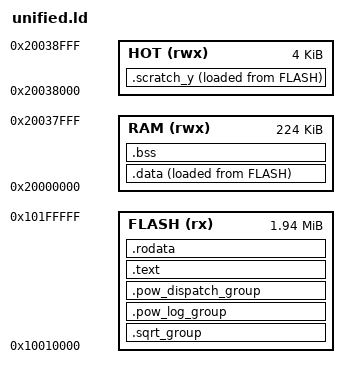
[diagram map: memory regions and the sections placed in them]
EXTERN(_ZN12compact_math2lnEd _ZN12compact_math3cosEd _ZN12compact_math3expEd _ZN12compact_math3powEdd _ZN12compact_math3sinEd _ZN12compact_math3tanEd _ZN12compact_math4acosEd _ZN12compact_math4asinEd _ZN12compact_math4atanEd _ZN12compact_math4sqrtEd _ZN12compact_math5log10Ed __aeabi_d2f __aeabi_d2iz __aeabi_d2lz __aeabi_d2uiz __aeabi_d2ulz __aeabi_dadd __aeabi_dcmpeq __aeabi_dcmpge __aeabi_dcmpgt __aeabi_dcmple __aeabi_dcmplt __aeabi_dcmpun __aeabi_ddiv __aeabi_dmul __aeabi_drsub __aeabi_dsub __aeabi_f2d __aeabi_f2iz __aeabi_f2uiz __aeabi_fadd __aeabi_fcmpeq __aeabi_fcmpge __aeabi_fcmpgt __aeabi_fcmple __aeabi_fcmplt __aeabi_fcmpun __aeabi_fdiv __aeabi_fmul __aeabi_frsub __aeabi_fsub __aeabi_i2d __aeabi_i2f __aeabi_idiv __aeabi_idiv0 __aeabi_idivmod __aeabi_l2d __aeabi_lasr __aeabi_ldiv0 __aeabi_ldivmod __aeabi_llsl __aeabi_llsr __aeabi_lmul __aeabi_mem_init __aeabi_ui2d __aeabi_ui2f __aeabi_uidiv __aeabi_uidivmod __aeabi_ul2d __aeabi_uldivmod mk61_m0_acos mk61_m0_asin mk61_m0_atan mk61_m0_atan_reduced mk61_m0_boundary128 mk61_m0_boundary128_compare mk61_m0_cr_acos mk61_m0_cr_asin mk61_m0_cr_atan mk61_m0_cr_cos mk61_m0_cr_exp mk61_m0_cr_ln mk61_m0_cr_log10 mk61_m0_cr_pow mk61_m0_cr_pow_refined mk61_m0_cr_sin mk61_m0_cr_tan mk61_m0_d2f_slow mk61_m0_d2iz_slow mk61_m0_d2lz_slow mk61_m0_d2ulz_slow mk61_m0_dadd_slow mk61_m0_ddiv_slow mk61_m0_divmod64 mk61_m0_dmul_slow mk61_m0_exp mk61_m0_exp_endpoint mk61_m0_exp_fraction_capture mk61_m0_exp_small_product48 mk61_m0_exp_small_product64 mk61_m0_exp_small_square48 mk61_m0_f2d_slow mk61_m0_fma mk61_m0_inline_seed_begin mk61_m0_inline_seed_done mk61_m0_ln mk61_m0_ln_approx mk61_m0_ln_special mk61_m0_log10 mk61_m0_log10_special mk61_m0_log_cube70 mk61_m0_log_product46 mk61_m0_log_product54 mk61_m0_log_ratio70 mk61_m0_log_ratio70_slow mk61_m0_math_udiv32 mk61_m0_mul_q62 mk61_m0_pow_argument mk61_m0_pow_argument_select mk61_m0_pow_center_quotient_end mk61_m0_pow_dispatch mk61_m0_pow_dispatch_ordinary mk61_m0_pow_exact_small mk61_m0_pow_exp_product mk61_m0_pow_exp_product_flash mk61_m0_pow_exp_table_product mk61_m0_pow_exp_table_product_flash mk61_m0_pow_fast mk61_m0_pow_log_ordinary mk61_m0_pow_log_select mk61_m0_pow_middle_interval mk61_m0_pow_midpoint mk61_m0_pow_near_one_binomial_dispatch mk61_m0_pow_negative_integer_dispatch mk61_m0_pow_positive_checked_dispatch mk61_m0_pow_rescue mk61_m0_pow_rsqrt_boundary mk61_m0_pow_rsqrt_fast mk61_m0_pow_rsqrt_point mk61_m0_pow_small_y mk61_m0_pow_square_exact mk61_m0_pow_tiny_or_cr mk61_m0_product62 mk61_m0_reciprocal1 mk61_m0_reciprocal1_after_second_product mk61_m0_reciprocal1_after_y_residual mk61_m0_reciprocal1_before_second_product mk61_m0_reciprocal1_certificate_begin mk61_m0_reciprocal1_certificate_down mk61_m0_reciprocal1_certificate_full mk61_m0_reciprocal1_certificate_up mk61_m0_reciprocal1_first_product mk61_m0_reciprocal1_half_normalization mk61_m0_reciprocal1_join mk61_m0_reciprocal1_pack_begin mk61_m0_reciprocal1_sw_after_second_product mk61_m0_reciprocal1_sw_after_y_residual mk61_m0_reciprocal1_sw_before_second_product mk61_m0_reciprocal1_sw_certificate_begin mk61_m0_reciprocal1_sw_certificate_down mk61_m0_reciprocal1_sw_certificate_full mk61_m0_reciprocal1_sw_certificate_up mk61_m0_reciprocal1_sw_first_product mk61_m0_reciprocal1_sw_from_guard mk61_m0_reciprocal1_sw_half_normalization mk61_m0_reciprocal1_sw_join mk61_m0_reciprocal1_sw_pack_begin mk61_m0_reciprocal1_sw_y_low_shift mk61_m0_reciprocal1_y_low_shift mk61_m0_reduce_pio2 mk61_m0_sdiv32 mk61_m0_sdivmod64 mk61_m0_sincos_reduced mk61_m0_sincos_small mk61_m0_sqrt mk61_m0_sqrt_slow mk61_m0_sqrt_special mk61_m0_sqrtf mk61_m0_tan_small mk61_m0_trig mk61_m0_trig_inverse_table mk61_m0_trig_large mk61_m0_trig_large_argument mk61_m0_trig_large_refine mk61_m0_trig_medium mk61_m0_trig_pack mk61_m0_trig_pi2_product mk61_m0_trig_product mk61_m0_udiv32 unified_math_init)
MEMORY {
 FLASH(rx) : ORIGIN = 0x10010000, LENGTH = 1984K
 RAM(rwx) : ORIGIN = 0x20000000, LENGTH = 224K
 HOT(rwx) : ORIGIN = 0x20038000, LENGTH = 4K
}
PHDRS { flash PT_LOAD FLAGS(5); hot PT_LOAD FLAGS(5); ram PT_LOAD FLAGS(6); }
SECTIONS {
 .sqrt_group : { *(.m0_sqrt_special) *(.m0_sqrt64_fixed.mk61_m0_sqrt) *(.m0_sqrt64_fixed.*) } > FLASH :flash
 .pow_log_group : { *(.m0_pow_log_selector) *(.m0_pow_extension) } > FLASH :flash
 .pow_dispatch_group : { *(.m0_pow_dispatch_extension) *(.m0_pow_extension_data) *(.m0_pow_argument_extension) } > FLASH :flash
 .text : { *(.text*) *(.m0_*) *(.time_critical*) } > FLASH :flash
 .rodata : { *(.rodata*) *(.data.rel.ro*) } > FLASH :flash
 .scratch_y : ALIGN(4) { __scratch_y_start__ = .; *(.scratch_y*) . = ALIGN(4); __scratch_y_end__ = .; } > HOT AT>FLASH :hot
 __scratch_y_source__ = LOADADDR(.scratch_y);
 .data : ALIGN(4) { __data_start__ = .; *(.data*) . = ALIGN(4); __data_end__ = .; } > RAM AT>FLASH :ram
 __data_source__ = LOADADDR(.data);
 .bss (NOLOAD) : ALIGN(4) { __bss_start__ = .; *(.bss*) *(COMMON) . = ALIGN(4); __bss_end__ = .; } > RAM :ram
 __StackBottom = 0x20039000; __StackTop = 0x20041000;
 /DISCARD/ : { *(.ARM.exidx*) *(.ARM.extab*) *(.comment) *(.note*) *(.ARM.attributes) *(.preinit_array*) *(.init_array*) }
}
ASSERT(SIZEOF(.scratch_y) <= 4080, "Math scratch bank exceeds 4080 bytes")
ASSERT(__scratch_y_end__ <= __StackBottom, "Math code overlaps stack")
ASSERT(__bss_end__ <= 0x20038000, "Math data overlaps scratch bank")
